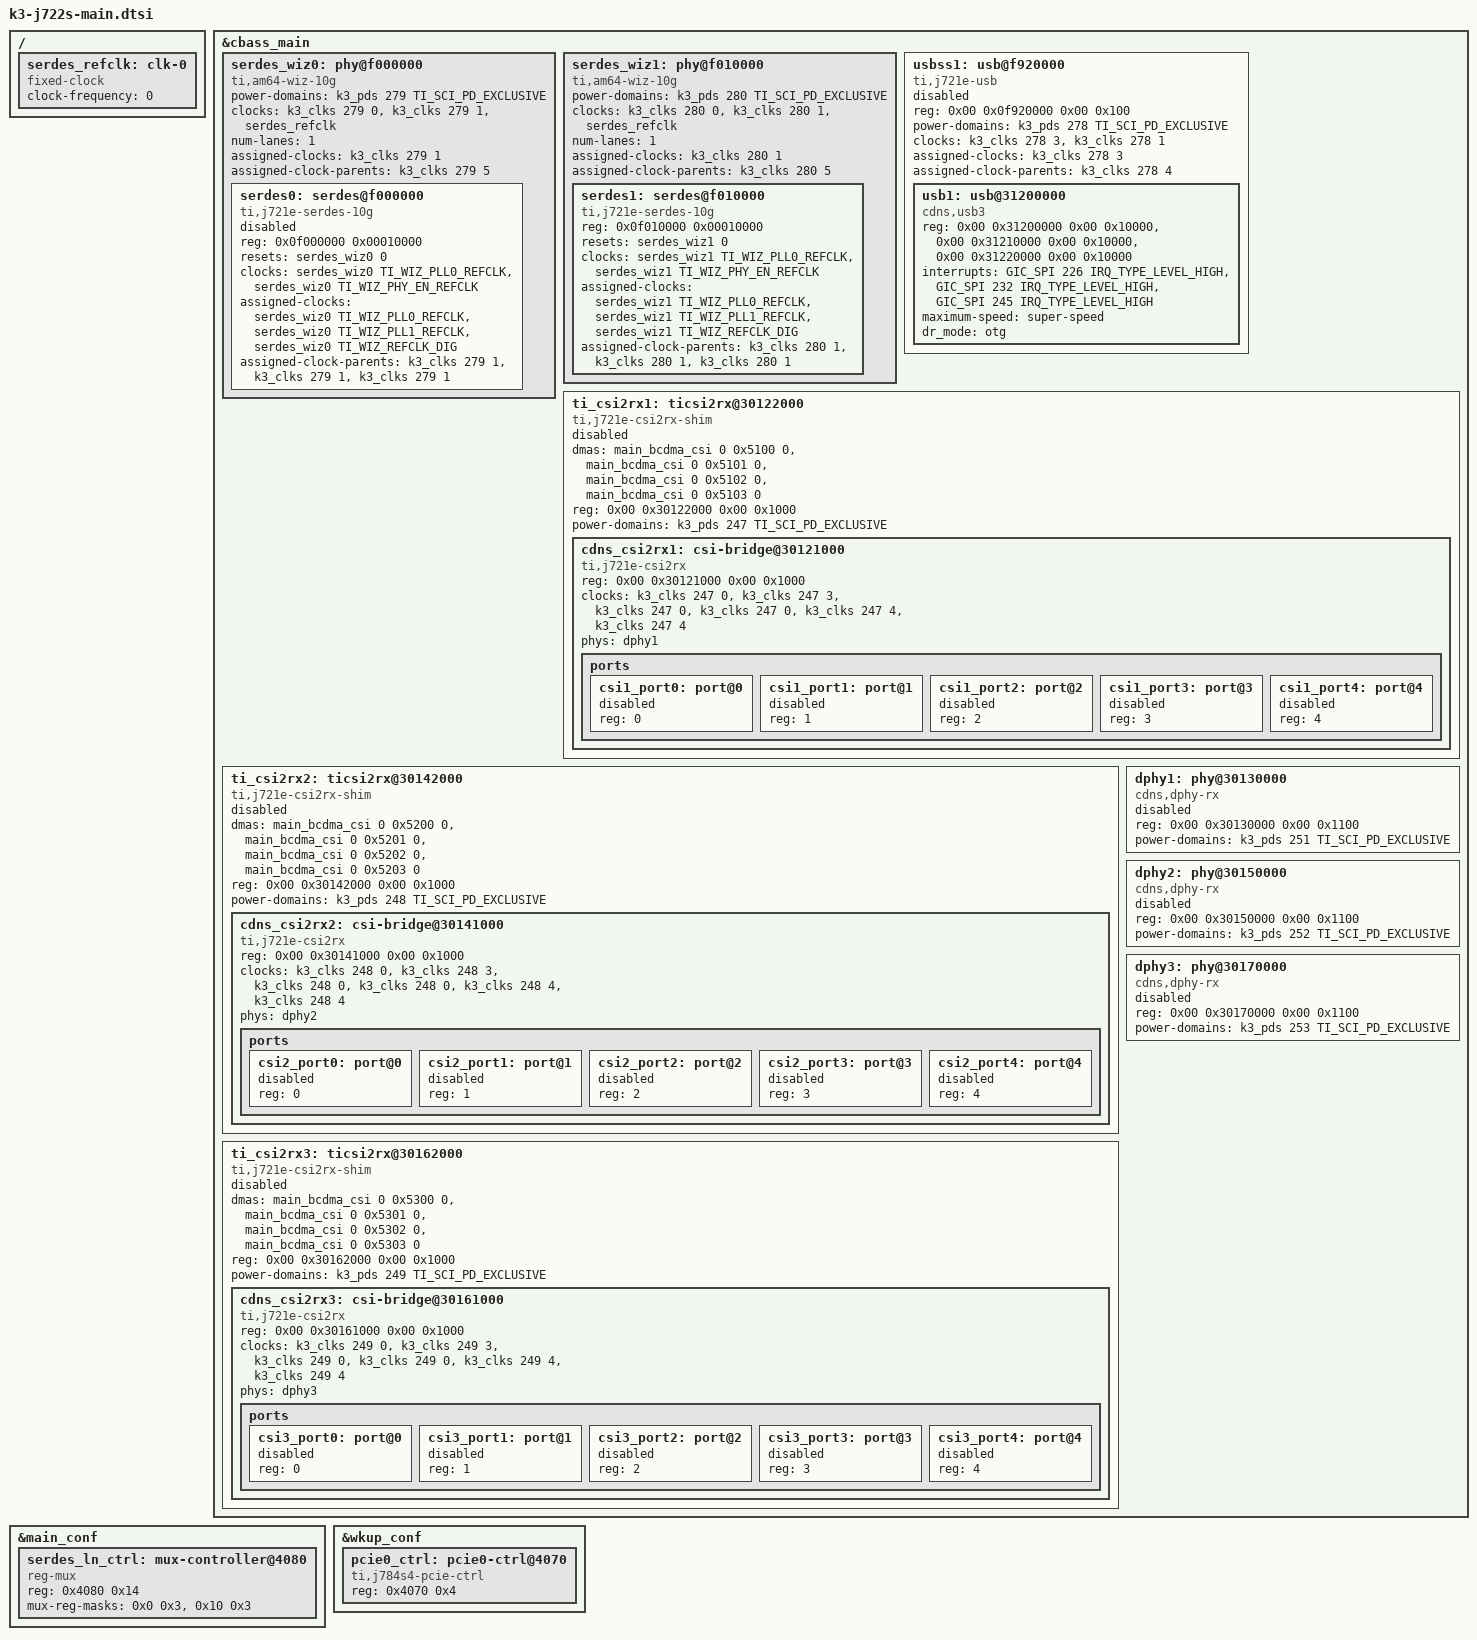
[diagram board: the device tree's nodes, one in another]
// SPDX-License-Identifier: GPL-2.0-only OR MIT
/*
 * Device Tree file for the J722S main domain peripherals
 * Copyright (C) 2023-2024 Texas Instruments Incorporated - https://www.ti.com/
 */

#include <dt-bindings/phy/phy-cadence.h>
#include <dt-bindings/phy/phy-ti.h>

/*
 * USB1 controller on AM62P and J722S are of different IP.
 * Delete AM62P's USBSS1 node definition and redefine it for J722S.
 */

/delete-node/ &usbss1;

/ {
	serdes_refclk: clk-0 {
		compatible = "fixed-clock";
		#clock-cells = <0>;
		clock-frequency = <0>;
	};
};

&cbass_main {
	serdes_wiz0: phy@f000000 {
		compatible = "ti,am64-wiz-10g";
		ranges = <0x0f000000 0x0 0x0f000000 0x00010000>;
		#address-cells = <1>;
		#size-cells = <1>;
		power-domains = <&k3_pds 279 TI_SCI_PD_EXCLUSIVE>;
		clocks = <&k3_clks 279 0>, <&k3_clks 279 1>, <&serdes_refclk>;
		clock-names = "fck", "core_ref_clk", "ext_ref_clk";
		num-lanes = <1>;
		#reset-cells = <1>;
		#clock-cells = <1>;

		assigned-clocks = <&k3_clks 279 1>;
		assigned-clock-parents = <&k3_clks 279 5>;

		serdes0: serdes@f000000 {
			compatible = "ti,j721e-serdes-10g";
			reg = <0x0f000000 0x00010000>;
			reg-names = "torrent_phy";
			resets = <&serdes_wiz0 0>;
			reset-names = "torrent_reset";
			clocks = <&serdes_wiz0 TI_WIZ_PLL0_REFCLK>,
				 <&serdes_wiz0 TI_WIZ_PHY_EN_REFCLK>;
			clock-names = "refclk", "phy_en_refclk";
			assigned-clocks = <&serdes_wiz0 TI_WIZ_PLL0_REFCLK>,
					  <&serdes_wiz0 TI_WIZ_PLL1_REFCLK>,
					  <&serdes_wiz0 TI_WIZ_REFCLK_DIG>;
			assigned-clock-parents = <&k3_clks 279 1>,
						 <&k3_clks 279 1>,
						 <&k3_clks 279 1>;
			#address-cells = <1>;
			#size-cells = <0>;
			#clock-cells = <1>;

			status = "disabled"; /* Needs lane config */
		};
	};

	serdes_wiz1: phy@f010000 {
		compatible = "ti,am64-wiz-10g";
		ranges = <0x0f010000 0x0 0x0f010000 0x00010000>;
		#address-cells = <1>;
		#size-cells = <1>;
		power-domains = <&k3_pds 280 TI_SCI_PD_EXCLUSIVE>;
		clocks = <&k3_clks 280 0>, <&k3_clks 280 1>, <&serdes_refclk>;
		clock-names = "fck", "core_ref_clk", "ext_ref_clk";
		num-lanes = <1>;
		#reset-cells = <1>;
		#clock-cells = <1>;

		assigned-clocks = <&k3_clks 280 1>;
		assigned-clock-parents = <&k3_clks 280 5>;

		serdes1: serdes@f010000 {
			compatible = "ti,j721e-serdes-10g";
			reg = <0x0f010000 0x00010000>;
			reg-names = "torrent_phy";
			resets = <&serdes_wiz1 0>;
			reset-names = "torrent_reset";
			clocks = <&serdes_wiz1 TI_WIZ_PLL0_REFCLK>,
				 <&serdes_wiz1 TI_WIZ_PHY_EN_REFCLK>;
			clock-names = "refclk", "phy_en_refclk";
			assigned-clocks = <&serdes_wiz1 TI_WIZ_PLL0_REFCLK>,
					  <&serdes_wiz1 TI_WIZ_PLL1_REFCLK>,
					  <&serdes_wiz1 TI_WIZ_REFCLK_DIG>;
			assigned-clock-parents = <&k3_clks 280 1>,
						 <&k3_clks 280 1>,
						 <&k3_clks 280 1>;
			#address-cells = <1>;
			#size-cells = <0>;
			#clock-cells = <1>;
		};
	};

	usbss1: usb@f920000 {
		compatible = "ti,j721e-usb";
		reg = <0x00 0x0f920000 0x00 0x100>;
		power-domains = <&k3_pds 278 TI_SCI_PD_EXCLUSIVE>;
		clocks = <&k3_clks 278 3>, <&k3_clks 278 1>;
		clock-names = "ref", "lpm";
		assigned-clocks = <&k3_clks 278 3>; /* USB2_REFCLK */
		assigned-clock-parents = <&k3_clks 278 4>; /* HF0SC0 */
		#address-cells = <2>;
		#size-cells = <2>;
		ranges;
		status = "disabled";

		usb1: usb@31200000{
			compatible = "cdns,usb3";
			reg = <0x00 0x31200000 0x00 0x10000>,
			      <0x00 0x31210000 0x00 0x10000>,
			      <0x00 0x31220000 0x00 0x10000>;
			reg-names = "otg",
				    "xhci",
				    "dev";
			interrupts = <GIC_SPI 226 IRQ_TYPE_LEVEL_HIGH>, /* irq.0 */
				     <GIC_SPI 232 IRQ_TYPE_LEVEL_HIGH>, /* irq.6 */
				     <GIC_SPI 245 IRQ_TYPE_LEVEL_HIGH>; /* otgirq */
			interrupt-names = "host",
					  "peripheral",
					  "otg";
			maximum-speed = "super-speed";
			dr_mode = "otg";
		};
	};

	ti_csi2rx1: ticsi2rx@30122000 {
		compatible = "ti,j721e-csi2rx-shim";
		dmas = <&main_bcdma_csi 0 0x5100 0>, <&main_bcdma_csi 0 0x5101 0>,
		       <&main_bcdma_csi 0 0x5102 0>, <&main_bcdma_csi 0 0x5103 0>;
		dma-names = "rx0", "rx1", "rx2", "rx3";
		reg = <0x00 0x30122000 0x00 0x1000>;
		power-domains = <&k3_pds 247 TI_SCI_PD_EXCLUSIVE>;
		#address-cells = <2>;
		#size-cells = <2>;
		ranges;
		status = "disabled";

		cdns_csi2rx1: csi-bridge@30121000 {
			compatible = "ti,j721e-csi2rx", "cdns,csi2rx";
			reg = <0x00 0x30121000 0x00 0x1000>;
			clocks = <&k3_clks 247 0>, <&k3_clks 247 3>, <&k3_clks 247 0>,
				 <&k3_clks 247 0>, <&k3_clks 247 4>, <&k3_clks 247 4>;
			clock-names = "sys_clk", "p_clk", "pixel_if0_clk",
				      "pixel_if1_clk", "pixel_if2_clk", "pixel_if3_clk";
			phys = <&dphy1>;
			phy-names = "dphy";

			ports {
				#address-cells = <1>;
				#size-cells = <0>;

				csi1_port0: port@0 {
					reg = <0>;
					status = "disabled";
				};

				csi1_port1: port@1 {
					reg = <1>;
					status = "disabled";
				};

				csi1_port2: port@2 {
					reg = <2>;
					status = "disabled";
				};

				csi1_port3: port@3 {
					reg = <3>;
					status = "disabled";
				};

				csi1_port4: port@4 {
					reg = <4>;
					status = "disabled";
				};
			};
		};
	};

	ti_csi2rx2: ticsi2rx@30142000 {
		compatible = "ti,j721e-csi2rx-shim";
		dmas = <&main_bcdma_csi 0 0x5200 0>, <&main_bcdma_csi 0 0x5201 0>,
		       <&main_bcdma_csi 0 0x5202 0>, <&main_bcdma_csi 0 0x5203 0>;
		dma-names = "rx0", "rx1", "rx2", "rx3";
		reg = <0x00 0x30142000 0x00 0x1000>;
		power-domains = <&k3_pds 248 TI_SCI_PD_EXCLUSIVE>;
		#address-cells = <2>;
		#size-cells = <2>;
		ranges;
		status = "disabled";

		cdns_csi2rx2: csi-bridge@30141000 {
			compatible = "ti,j721e-csi2rx", "cdns,csi2rx";
			reg = <0x00 0x30141000 0x00 0x1000>;
			clocks = <&k3_clks 248 0>, <&k3_clks 248 3>, <&k3_clks 248 0>,
				 <&k3_clks 248 0>, <&k3_clks 248 4>, <&k3_clks 248 4>;
			clock-names = "sys_clk", "p_clk", "pixel_if0_clk",
				      "pixel_if1_clk", "pixel_if2_clk", "pixel_if3_clk";
			phys = <&dphy2>;
			phy-names = "dphy";

			ports {
				#address-cells = <1>;
				#size-cells = <0>;

				csi2_port0: port@0 {
					reg = <0>;
					status = "disabled";
				};

				csi2_port1: port@1 {
					reg = <1>;
					status = "disabled";
				};

				csi2_port2: port@2 {
					reg = <2>;
					status = "disabled";
				};

				csi2_port3: port@3 {
					reg = <3>;
					status = "disabled";
				};

				csi2_port4: port@4 {
					reg = <4>;
					status = "disabled";
				};
			};
		};
	};

	ti_csi2rx3: ticsi2rx@30162000 {
		compatible = "ti,j721e-csi2rx-shim";
		dmas = <&main_bcdma_csi 0 0x5300 0>, <&main_bcdma_csi 0 0x5301 0>,
		       <&main_bcdma_csi 0 0x5302 0>, <&main_bcdma_csi 0 0x5303 0>;
		dma-names = "rx0", "rx1";
		reg = <0x00 0x30162000 0x00 0x1000>;
		power-domains = <&k3_pds 249 TI_SCI_PD_EXCLUSIVE>;
		#address-cells = <2>;
		#size-cells = <2>;
		ranges;
		status = "disabled";

		cdns_csi2rx3: csi-bridge@30161000 {
			compatible = "ti,j721e-csi2rx", "cdns,csi2rx";
			reg = <0x00 0x30161000 0x00 0x1000>;
			clocks = <&k3_clks 249 0>, <&k3_clks 249 3>, <&k3_clks 249 0>,
				 <&k3_clks 249 0>, <&k3_clks 249 4>, <&k3_clks 249 4>;
			clock-names = "sys_clk", "p_clk", "pixel_if0_clk",
				      "pixel_if1_clk", "pixel_if2_clk", "pixel_if3_clk";
			phys = <&dphy3>;
			phy-names = "dphy";

			ports {
				#address-cells = <1>;
				#size-cells = <0>;

				csi3_port0: port@0 {
					reg = <0>;
					status = "disabled";
				};

				csi3_port1: port@1 {
					reg = <1>;
					status = "disabled";
				};

				csi3_port2: port@2 {
					reg = <2>;
					status = "disabled";
				};

				csi3_port3: port@3 {
					reg = <3>;
					status = "disabled";
				};

				csi3_port4: port@4 {
					reg = <4>;
					status = "disabled";
				};
			};
		};
	};

	dphy1: phy@30130000 {
		compatible = "cdns,dphy-rx";
		reg = <0x00 0x30130000 0x00 0x1100>;
		#phy-cells = <0>;
		power-domains = <&k3_pds 251 TI_SCI_PD_EXCLUSIVE>;
		status = "disabled";
	};

	dphy2: phy@30150000 {
		compatible = "cdns,dphy-rx";
		reg = <0x00 0x30150000 0x00 0x1100>;
		#phy-cells = <0>;
		power-domains = <&k3_pds 252 TI_SCI_PD_EXCLUSIVE>;
		status = "disabled";
	};

	dphy3: phy@30170000 {
		compatible = "cdns,dphy-rx";
		reg = <0x00 0x30170000 0x00 0x1100>;
		#phy-cells = <0>;
		power-domains = <&k3_pds 253 TI_SCI_PD_EXCLUSIVE>;
		status = "disabled";
	};
};

/* MCU domain overrides */

&main_conf {
	serdes_ln_ctrl: mux-controller@4080 {
		compatible = "reg-mux";
		reg = <0x4080 0x14>;
		#mux-control-cells = <1>;
		mux-reg-masks = <0x0 0x3>, /* SERDES0 lane0 select */
				<0x10 0x3>; /* SERDES1 lane0 select */
	};
};

&wkup_conf {
	pcie0_ctrl: pcie0-ctrl@4070 {
		compatible = "ti,j784s4-pcie-ctrl", "syscon";
		reg = <0x4070 0x4>;
	};
};
